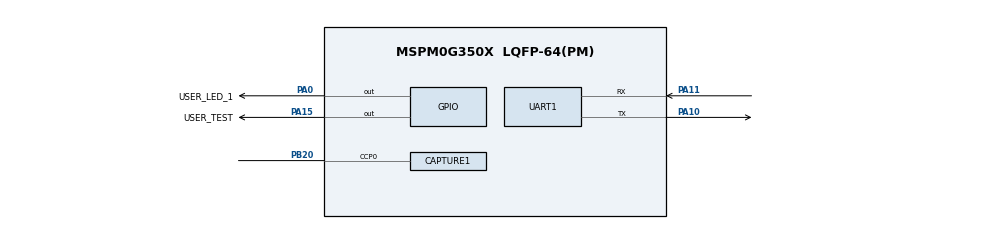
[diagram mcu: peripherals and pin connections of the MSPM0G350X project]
/**
 * @cliArgs --device "MSPM0G350X" --part "Default" --package "LQFP-64(PM)" --product "mspm0_sdk@2.03.00.08"
 * @versions {"tool":"1.22.0+3893"}
 */

/**
 * Import the modules used in this configuration.
 */
const CAPTURE  = scripting.addModule("/ti/driverlib/CAPTURE", {}, false);
const CAPTURE1 = CAPTURE.addInstance();
const GPIO     = scripting.addModule("/ti/driverlib/GPIO", {}, false);
const GPIO1    = GPIO.addInstance();
const SYSCTL   = scripting.addModule("/ti/driverlib/SYSCTL");
const TIMER    = scripting.addModule("/ti/driverlib/TIMER", {}, false);
const TIMER1   = TIMER.addInstance();
const UART     = scripting.addModule("/ti/driverlib/UART", {}, false);
const UART1    = UART.addInstance();

/**
 * Write custom configuration values to the imported modules.
 */
CAPTURE1.$name                       = "CAPTURE_0";
CAPTURE1.captMode                    = "PULSE_WIDTH_UP";
CAPTURE1.captEdgeDetection           = "FALLING";
CAPTURE1.captureInputMode            = "multi";
CAPTURE1.multi_countMode             = "DL_TIMER_COUNT_MODE_UP";
CAPTURE1.multi_countRep              = "DL_TIMER_REPEAT_MODE_ENABLED";
CAPTURE1.ccIndexMulti                = [0,1];
CAPTURE1.multi_ch1_input_mode        = "DL_TIMER_CC_IN_SEL_CCPX_PAIR";
CAPTURE1.multi_ch1_captEdgeDetection = "DL_TIMER_CC_CCOND_TRIG_FALL";
CAPTURE1.multi_cvae                  = "DL_TIMER_COUNT_AFTER_EN_NO_CHANGE";
CAPTURE1.timerPeriod                 = "100s";
CAPTURE1.interrupts                  = ["CC1_UP"];
CAPTURE1.peripheral.$assign          = "TIMG12";
CAPTURE1.peripheral.ccp0Pin.$assign  = "PB20";
CAPTURE1.ccp0PinConfig.$name         = "ti_driverlib_gpio_GPIOPinGeneric2";

const Board = scripting.addModule("/ti/driverlib/Board", {}, false);

GPIO1.$name                          = "GPIO_LEDS";
GPIO1.associatedPins.create(2);
GPIO1.associatedPins[0].$name        = "USER_LED_1";
GPIO1.associatedPins[0].initialValue = "SET";
GPIO1.associatedPins[0].pin.$assign  = "PA0";
GPIO1.associatedPins[1].$name        = "USER_TEST";
GPIO1.associatedPins[1].initialValue = "SET";
GPIO1.associatedPins[1].pin.$assign  = "PA15";

SYSCTL.validateClkStatus     = true;
SYSCTL.forceDefaultClkConfig = true;

TIMER1.$name              = "TIMER_0";
TIMER1.timerClkDiv        = 8;
TIMER1.timerClkSrc        = "LFCLK";
TIMER1.timerMode          = "PERIODIC";
TIMER1.interrupts         = ["ZERO"];
TIMER1.timerPeriod        = "1000 ms";
TIMER1.timerStartTimer    = true;
TIMER1.peripheral.$assign = "TIMG0";

UART1.$name                             = "UART_0";
UART1.rxFifoThreshold                   = "DL_UART_RX_FIFO_LEVEL_ONE_ENTRY";
UART1.enabledInterrupts                 = ["DMA_DONE_TX","EOT_DONE"];
UART1.targetBaudRate                    = 115200;
UART1.uartClkDiv                        = "8";
UART1.enableFIFO                        = true;
UART1.txFifoThreshold                   = "DL_UART_TX_FIFO_LEVEL_ONE_ENTRY";
UART1.enabledDMATXTriggers              = "DL_UART_DMA_INTERRUPT_TX";
UART1.peripheral.$assign                = "UART0";
UART1.peripheral.rxPin.$assign          = "PA11";
UART1.peripheral.txPin.$assign          = "PA10";
UART1.txPinConfig.$name                 = "ti_driverlib_gpio_GPIOPinGeneric0";
UART1.rxPinConfig.$name                 = "ti_driverlib_gpio_GPIOPinGeneric1";
UART1.DMA_CHANNEL_TX.$name              = "DMA_CH0";
UART1.DMA_CHANNEL_TX.addressMode        = "b2f";
UART1.DMA_CHANNEL_TX.srcLength          = "BYTE";
UART1.DMA_CHANNEL_TX.dstLength          = "BYTE";
UART1.DMA_CHANNEL_TX.peripheral.$assign = "DMA_CH0";

/**
 * Pinmux solution for unlocked pins/peripherals. This ensures that minor changes to the automatic solver in a future
 * version of the tool will not impact the pinmux you originally saw.  These lines can be completely deleted in order to
 * re-solve from scratch.
 */
Board.peripheral.$suggestSolution          = "DEBUGSS";
Board.peripheral.swclkPin.$suggestSolution = "PA20";
Board.peripheral.swdioPin.$suggestSolution = "PA19";
SYSCTL.peripheral.$suggestSolution         = "SYSCTL";
